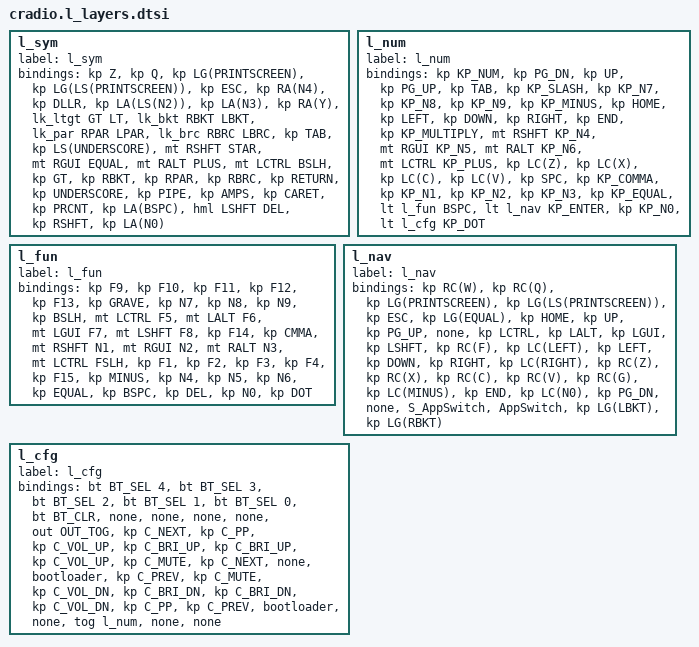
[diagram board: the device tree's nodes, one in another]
/*
 Building for a 36 key on a 42 key board (outside column is unused)
 */

//                                       Symbol & math
//╭────────────────────────────────────────────╮ ╭──────────────────────────────────────────╮
//|    Z   |    Q    | ScrCp | SelCp |   ESC   | |   ¢   |    $   |    €   |    £   |   ¥   |
//|    <   |    [    |   (   |   {   |   TAB   | |   ¡   |    *   |    =   |    +   |   \   |
//|    >   |    ]    |   )   |   }   |   RET   | |   _   |    |   |    &   |    ^   |   %   |
//╰──────────────────╮       |  BKSP |   DEL   | |       |    °   |    ·   ╭────────────────╯
//                   ╰─────────────────────────╯ ╰─────────────────────────╯
                l_sym {
                    label = "l_sym";
                    bindings = <
&kp Z &kp Q &kp LG(PRINTSCREEN) &kp LG(LS(PRINTSCREEN)) &kp ESC             &kp RA(N4) &kp DLLR  &kp LA(LS(N2)) &kp LA(N3) &kp RA(Y)
&lk_ltgt GT LT  &lk_bkt RBKT LBKT &lk_par RPAR LPAR &lk_brc RBRC LBRC &kp TAB  &kp LS(UNDERSCORE) &mt RSHFT STAR  &mt RGUI EQUAL &mt RALT PLUS  &mt LCTRL BSLH
&kp GT  &kp RBKT &kp RPAR &kp RBRC &kp RETURN                     &kp UNDERSCORE  &kp PIPE  &kp AMPS     &kp CARET &kp PRCNT
                &kp LA(BSPC)   &hml LSHFT DEL                     &kp RSHFT      &kp LA(N0)
                    >;
                };

//                                          Nav & NumPad (standard)
//╭────────────────────────────────────────────╮ ╭────────────────────────────────────────╮
//|   NUM  |  HOME  |   UP   |  PG_UP |  TAB   | |    /   |   7   |   8   |   9   |   -   |
//|  Lword |  LEFT  |  DOWN  |   RGT  | Rword  | |    *   |   4   |   5   |   6   |   +   |
//|   SPC  |   END  |  DOWN  |  PG_DN |  SPC   | |    ,   |   1   |   2   |   3   |   =   |
//╰─────────────────╮  MENU  |  BSPC  | ENTER  | |    0   |   .   | ----- ╭───────────────╯
//                  ╰──────────────────────────╯ ╰────────────────────────╯
                    l_num {
                        label = "l_num";
                        bindings = <

 &kp KP_NUM    &kp PG_DN &kp UP    &kp PG_UP &kp TAB        &kp KP_SLASH    &kp KP_N7 &kp KP_N8 &kp KP_N9 &kp KP_MINUS
 &kp HOME  &kp LEFT  &kp DOWN  &kp RIGHT  &kp END &kp KP_MULTIPLY &mt RSHFT KP_N4 &mt RGUI KP_N5 &mt RALT KP_N6 &mt LCTRL KP_PLUS
 &kp LC(Z)     &kp LC(X) &kp LC(C) &kp LC(V)  &kp SPC       &kp KP_COMMA    &kp KP_N1 &kp KP_N2 &kp KP_N3 &kp KP_EQUAL
                     &lt l_fun BSPC &lt l_nav KP_ENTER  &kp KP_N0       &lt l_cfg KP_DOT
                        >;
                };


//                                         Fkey & Num Row (optimized)
//╭────────────────────────────────────────────╮ ╭───────────────────────────────────────╮
//|    F9   |  F10   |  F11   |  F12   |  F13  | |   `   |   6   |   7   |   8   |   \   |
//|   C/F5  |  A/F6  |  G/F7  |  S/F8  |  F14  | |   ,   |  S/1  |  G/5  |  A/9  |  C//  |
//|    F1   |   F2   |   F3   |   F4   |  F15  | |   -   |   2   |   3   |   4   |   =   |
//╰──────────────────╮        |  dwdlt | dwdrt | |   0   |   .   |   ;   ╭───────────────╯
//                   ╰─────────────────────────╯ ╰───────────────────────╯

                    l_fun {
                        label = "l_fun";
                        bindings = <

 &kp F9       &kp F10     &kp F11      &kp F12      &kp F13 &kp GRAVE &kp N7       &kp N8      &kp N9      &kp BSLH
 &mt LCTRL F5 &mt LALT F6 &mt LGUI F7  &mt LSHFT F8 &kp F14 &kp CMMA  &mt RSHFT N1 &mt RGUI N2 &mt RALT N3 &mt LCTRL FSLH
 &kp F1       &kp F2      &kp F3       &kp F4       &kp F15 &kp MINUS &kp N4       &kp N5      &kp N6      &kp EQUAL
                       &kp BSPC     &kp DEL      &kp N0    &kp DOT
                        >;
                };


//                                     shorcuts & Navigation
//╭────────────────────────────────────────────╮ ╭──────────────────────────────────────────╮
//|  close |   quit  | ScrCp | SelCp |   ESC   | |       |  HOME  |   UP   |  PG_UP |       |
//|   ctrl |   alt   |  gui  |  shft |   Find  | | Lword |  LEFT  |  DOWN  |   RGT  | Rword |
//|  undo  |   cut   |  copy |  pste | findAgn | |       |   END  |        |  PG_DN |       |
//╰──────────────────╮       | dwdlt |  dwdrt  | |  back |  fwd   |        ╭────────────────╯
//                   ╰─────────────────────────╯ ╰─────────────────────────╯
                l_nav {
                    label = "l_nav";
                    bindings = <
 &kp RC(W) &kp RC(Q) &kp LG(PRINTSCREEN) &kp LG(LS(PRINTSCREEN)) &kp ESC  &kp LG(EQUAL) &kp HOME &kp UP     &kp PG_UP &none
 &kp LCTRL  &kp LALT &kp LGUI &kp LSHFT   &kp RC(F)             &kp LC(LEFT)  &kp LEFT &kp DOWN   &kp RIGHT &kp LC(RIGHT)
 &kp RC(Z)  &kp RC(X) &kp RC(C) &kp RC(V) &kp RC(G)             &kp LC(MINUS) &kp END  &kp LC(N0) &kp PG_DN &none
                   &S_AppSwitch    &AppSwitch        &kp LG(LBKT) &kp LG(RBKT)
                    >;
                };

//                                     Keyboard & System Settings
                    l_cfg {
                        label = "l_cfg";
                        bindings = <
//&none &none &none &none &none &none &none &none &none &none &none &none
   &bt BT_SEL 4 &bt BT_SEL 3 &bt BT_SEL 2 &bt BT_SEL 1 &bt BT_SEL 0 &bt BT_CLR   &none        &none      &none      &none
        &out OUT_TOG &kp C_NEXT   &kp C_PP     &kp C_VOL_UP &kp C_BRI_UP &kp C_BRI_UP &kp C_VOL_UP &kp C_MUTE &kp C_NEXT &none
        &bootloader  &kp C_PREV   &kp C_MUTE   &kp C_VOL_DN &kp C_BRI_DN &kp C_BRI_DN &kp C_VOL_DN &kp C_PP   &kp C_PREV   &bootloader
                              &none &tog l_num     &none   &none
                        >;
                };
